VERSION "1.0"

NS_ :

BS_:

BU_: Engine Display

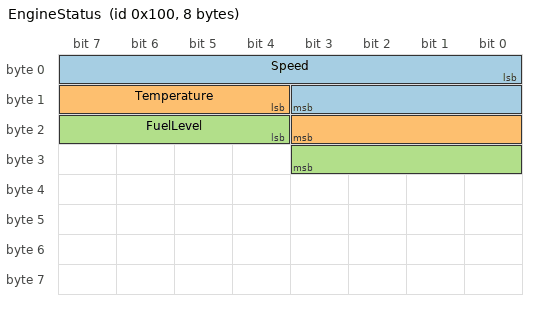
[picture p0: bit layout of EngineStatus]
BO_ 256 EngineStatus: 8 Engine
 SG_ Speed : 0|12@1+ (1,0) [0|4095] "rpm" Display
 SG_ Temperature : 12|8@1+ (1,-40) [-40|215] "degC" Display
 SG_ FuelLevel : 20|8@1+ (0.5,0) [0|100] "%" Display

BO_ 257 VehicleSpeed: 4 Engine
 SG_ SpeedKm : 0|16@1+ (0.1,0) [0|350] "km/h" Display

BO_ 512 ControlCommand: 2 Display
 SG_ AC_Switch : 0|1@1+ (1,0) [0|1] "" Engine
